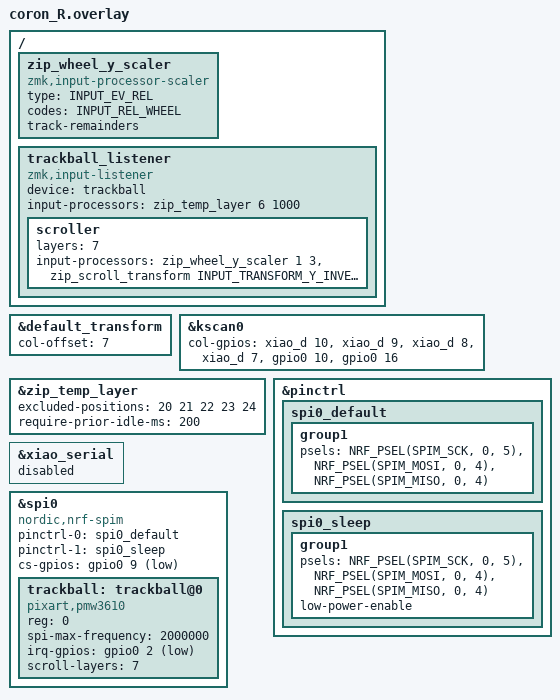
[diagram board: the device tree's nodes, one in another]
#include "coron.dtsi"
#include <input/processors.dtsi>
#include <dt-bindings/zmk/input_transform.h>
#include <input/processors/runtime-input-processor.dtsi>
#include <behaviors/battery_history_request.dtsi>

&default_transform {
    col-offset = <7>;
};

&kscan0 {
    col-gpios
        = <&xiao_d 10 GPIO_ACTIVE_HIGH>
        , <&xiao_d 9 GPIO_ACTIVE_HIGH>
        , <&xiao_d 8 GPIO_ACTIVE_HIGH>
        , <&xiao_d 7 GPIO_ACTIVE_HIGH>
        , <&gpio0 10 GPIO_ACTIVE_HIGH>
        , <&gpio0 16 GPIO_ACTIVE_HIGH> /* Col 5: P0.16 (NFC2) */
        ;
};

&zip_temp_layer {
    excluded-positions = <
        20 // H
        21 // J
        22 // K
        23 // L
        24 // @
    >;
    require-prior-idle-ms = <200>;
};

/ {
    /omit-if-no-ref/ zip_wheel_y_scaler: zip_wheel_y_scaler {
        compatible = "zmk,input-processor-scaler";
        #input-processor-cells = <2>;
        type = <INPUT_EV_REL>;
        codes = <INPUT_REL_WHEEL>;
        track-remainders;
    };

    trackball_listener {
        scroller {
            layers = <7>;
            /* Y 方向のみ独立減速。ドライバ側 SCROLL_TICK と組合せて最終速度を決める。
             *   1 1 = 素通り, 1 2 = 50%, 1 4 = 25%, 1 8 = 12.5%, 1 16 = 6.25%
             */
            input-processors = <
                &zip_wheel_y_scaler 1 3
                &zip_scroll_transform INPUT_TRANSFORM_Y_INVERT
            >;
        };
        status = "okay";
        compatible = "zmk,input-listener";
        device = <&trackball>;

        input-processors = <&zip_temp_layer 6 1000>;
    };
};

&pinctrl {
    spi0_default: spi0_default {
        group1 {
            psels = <NRF_PSEL(SPIM_SCK, 0, 5)>,
                <NRF_PSEL(SPIM_MOSI, 0, 4)>,
                <NRF_PSEL(SPIM_MISO, 0, 4)>;
        };
    };

    spi0_sleep: spi0_sleep {
        group1 {
            psels = <NRF_PSEL(SPIM_SCK, 0, 5)>,
                <NRF_PSEL(SPIM_MOSI, 0, 4)>,
                <NRF_PSEL(SPIM_MISO, 0, 4)>;
            low-power-enable;
        };
    };
};

&xiao_serial { status = "disabled"; };

&spi0 {
    status = "okay";
    compatible = "nordic,nrf-spim";
    pinctrl-0 = <&spi0_default>;
    pinctrl-1 = <&spi0_sleep>;
    pinctrl-names = "default", "sleep";
    cs-gpios = <&gpio0 9 GPIO_ACTIVE_LOW>;

    trackball: trackball@0 {
        status = "okay";
        compatible = "pixart,pmw3610";
        reg = <0>;
        spi-max-frequency = <2000000>;
        irq-gpios = <&gpio0 2 (GPIO_ACTIVE_LOW | GPIO_PULL_UP)>;
        scroll-layers = <7>;
    };
};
